VERSION "1.0"

NS_ :

BS_:

BU_: MASTER SLAVE

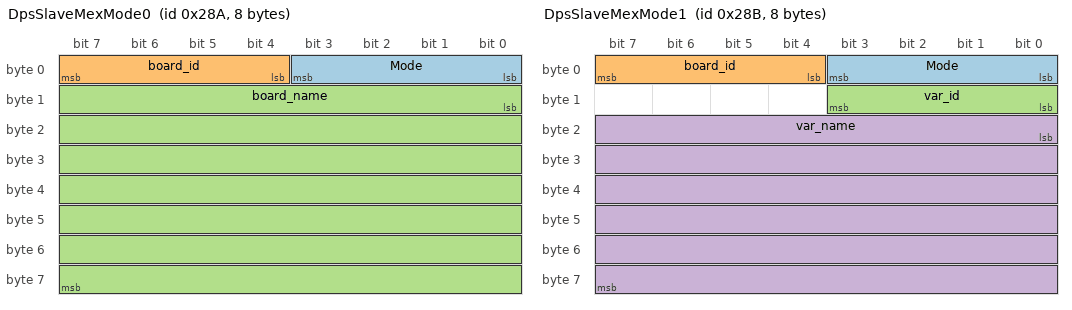
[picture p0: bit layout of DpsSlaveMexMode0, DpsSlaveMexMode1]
BO_ 650 DpsSlaveMexMode0: 8 SLAVE
 SG_ Mode: 0|4@1+ (1,0) [0|15] "slave mex type" MASTER
 SG_ board_id : 4|4@1+ (1,0) [0|15] "slave board id" MASTER
 SG_ board_name : 8|56@1+ (1,0) [0|0] "slave board name" MASTER

BO_ 651 DpsSlaveMexMode1: 8 SLAVE
 SG_ Mode: 0|4@1+ (1,0) [0|15] "slave mex type" MASTER
 SG_ board_id : 4|4@1+ (1,0) [0|15] "slave board id" MASTER
 SG_ var_id : 8|4@1+ (1,0) [0|15] "slave var id" MASTER
 SG_ var_name : 16|48@1+ (1,0) [0|0] "slave var name" MASTER

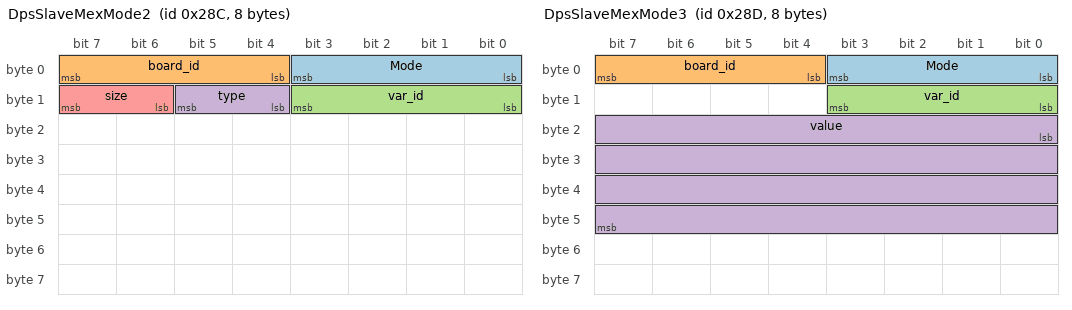
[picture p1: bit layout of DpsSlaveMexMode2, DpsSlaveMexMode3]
BO_ 652 DpsSlaveMexMode2: 8 SLAVE
 SG_ Mode: 0|4@1+ (1,0) [0|15] "slave mex type" MASTER
 SG_ board_id : 4|4@1+ (1,0) [0|15] "slave board id" MASTER
 SG_ var_id : 8|4@1+ (1,0) [0|15] "slave var id" MASTER
 SG_ type : 12|2@1+ (1,0) [0|2] "slave var type" MASTER
 SG_ size : 14|2@1+ (1,0) [0|2] "slave var size" MASTER

BO_ 653 DpsSlaveMexMode3: 8 SLAVE
 SG_ Mode: 0|4@1+ (1,0) [0|15] "slave mex type" MASTER
 SG_ board_id : 4|4@1+ (1,0) [0|15] "slave board id" MASTER
 SG_ var_id : 8|4@1+ (1,0) [0|15] "slave var id" MASTER
 SG_ value : 16|32@1+ (1,0) [0|2] "slave var value" MASTER

BO_ 660 DpsMasterMexMode0: 8 SLAVE
 SG_ Mode: 0|4@1+ (1,0) [0|15] "slave mex type" SLAVE
 SG_ reserved: 4|1@1+ (1,0) [0|0] "" SLAVE

BO_ 661 DpsMasterMexMode1: 8 SLAVE
 SG_ Mode: 0|4@1+ (1,0) [0|15] "slave mex type" SLAVE
 SG_ board_id : 4|4@1+ (1,0) [0|15] "slave board id" SLAVE

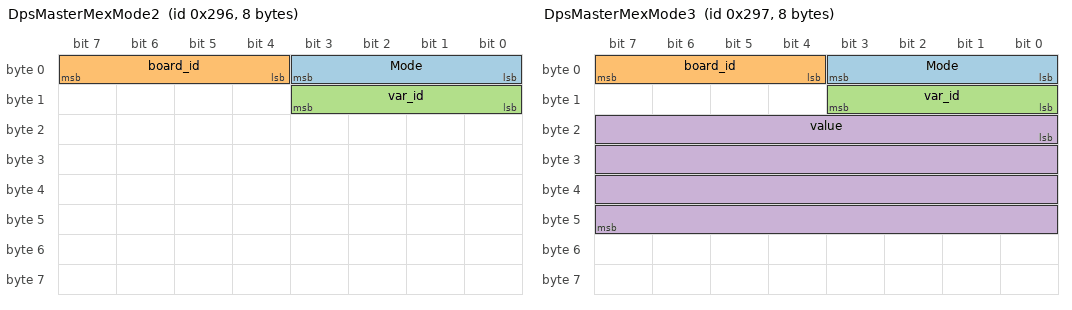
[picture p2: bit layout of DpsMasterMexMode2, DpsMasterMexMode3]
BO_ 662 DpsMasterMexMode2: 8 SLAVE
 SG_ Mode: 0|4@1+ (1,0) [0|15] "slave mex type" SLAVE
 SG_ board_id : 4|4@1+ (1,0) [0|15] "slave board id" SLAVE
 SG_ var_id : 8|4@1+ (1,0) [0|15] "slave var id" SLAVE

BO_ 663 DpsMasterMexMode3: 8 SLAVE
 SG_ Mode: 0|4@1+ (1,0) [0|15] "slave mex type" SLAVE
 SG_ board_id : 4|4@1+ (1,0) [0|15] "slave board id" SLAVE
 SG_ var_id : 8|4@1+ (1,0) [0|15] "slave var id" SLAVE
 SG_ value: 16|32@1+ (1,0) [0|0] "slave var value" SLAVE

VAL_ 650 Mode 0 "BoardName" 1 "VarName" 2 "VarMetadata" 3 "VarValue"
VAL_ 651 Mode 0 "Discover Boards" 1 "Request Infos Board" 2 "Req var value" 3 "Update var value"
VAL_ 650 type 0 "Integer" 1 "Float" 2 "String"
VAL_ 650 size 0 "8-bit" 1 "16-bit" 2 "32-bit"
